AUTOSAR XML (schema 4-3-0)
package /DBCImport/CANTP
  can tp config CanTpConfig_Project: communication-cluster=Project, can-tp-ecu=ECU1
    4 x can tp channel, all with channel-mode=HALF-DUPLEX-MODE:
      CanTpChannel{0..3}: channel-id={0..3}
    tp-connections:
      addressing-format=STANDARD, can-tp-channel=CanTpChannel1, data-pdu=NPdu_GST_Msg_TP2, flow-control-pdu=NPdu_ECU1_Msg_TP2, max-block-size=0, padding-activation=true, ta-type=PHYSICAL, tp-sdu=ISignalIPdu_GST_Msg_TP2
      addressing-format=STANDARD, can-tp-channel=CanTpChannel0, data-pdu=NPdu_GST_Msg_TP1, flow-control-pdu=NPdu_ECU1_Msg_TP1, max-block-size=0, padding-activation=true, ta-type=PHYSICAL, tp-sdu=ISignalIPdu_GST_Msg_TP1
      addressing-format=STANDARD, can-tp-channel=CanTpChannel2, data-pdu=NPdu_ECU1_GST_Msg_TP, flow-control-pdu=NPdu_GST_Msg_TP_Phys, max-block-size=0, padding-activation=true, ta-type=PHYSICAL, tp-sdu=DcmIPdu_ECU1_GST_Msg_TP
      addressing-format=STANDARD, can-tp-channel=CanTpChannel2, data-pdu=NPdu_GST_Msg_TP_Phys, flow-control-pdu=NPdu_ECU1_GST_Msg_TP, max-block-size=0, padding-activation=true, ta-type=PHYSICAL, tp-sdu=DcmIPdu_GST_Msg_TP_Phys
      addressing-format=STANDARD, can-tp-channel=CanTpChannel1, data-pdu=NPdu_ECU1_Msg_TP2, flow-control-pdu=NPdu_GST_Msg_TP2, max-block-size=0, padding-activation=true, ta-type=PHYSICAL, tp-sdu=ISignalIPdu_ECU1_Msg_TP2
      addressing-format=STANDARD, can-tp-channel=CanTpChannel3, data-pdu=NPdu_GST_Msg_TP_Func, max-block-size=0, padding-activation=true, ta-type=FUNCTIONAL, tp-sdu=DcmIPdu_GST_Msg_TP_Func
      addressing-format=STANDARD, can-tp-channel=CanTpChannel0, data-pdu=NPdu_ECU1_Msg_TP1, flow-control-pdu=NPdu_GST_Msg_TP1, max-block-size=0, padding-activation=true, ta-type=PHYSICAL, tp-sdu=ISignalIPdu_ECU1_Msg_TP1
    can tp node ECU1: connector=Conn_ECU1_Project
package /DBCImport/SWCComposition
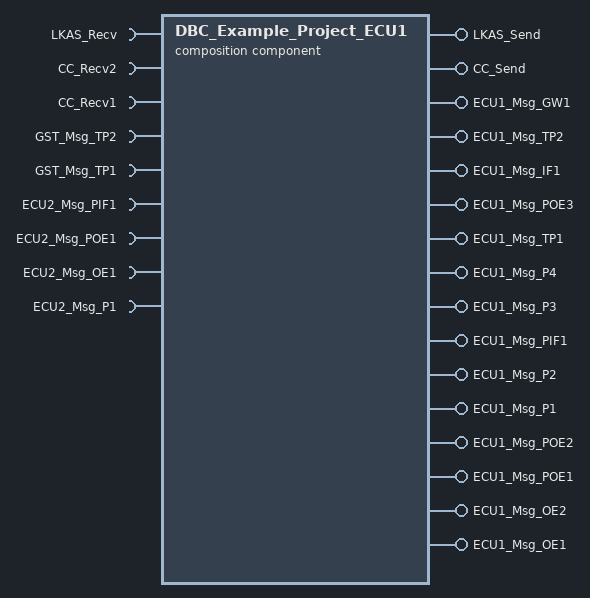
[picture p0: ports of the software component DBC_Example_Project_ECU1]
  composition sw component type DBC_Example_Project_ECU1
    16 x provide port:
      LKAS_Send: provided-interface=LKAS_Send
      CC_Send: provided-interface=CC_Send
      ECU1_Msg_GW1: provided-interface=ECU1_Msg_GW1
      ECU1_Msg_TP2: provided-interface=ECU1_Msg_TP2
      ECU1_Msg_IF1: provided-interface=ECU1_Msg_IF1
      ECU1_Msg_POE3: provided-interface=ECU1_Msg_POE3
      ECU1_Msg_TP1: provided-interface=ECU1_Msg_TP1
      ECU1_Msg_P4: provided-interface=ECU1_Msg_P4
      ECU1_Msg_P3: provided-interface=ECU1_Msg_P3
      ECU1_Msg_PIF1: provided-interface=ECU1_Msg_PIF1
      ECU1_Msg_P2: provided-interface=ECU1_Msg_P2
      ECU1_Msg_P1: provided-interface=ECU1_Msg_P1
      ECU1_Msg_POE2: provided-interface=ECU1_Msg_POE2
      ECU1_Msg_POE1: provided-interface=ECU1_Msg_POE1
      ECU1_Msg_OE2: provided-interface=ECU1_Msg_OE2
      ECU1_Msg_OE1: provided-interface=ECU1_Msg_OE1
    9 x require port:
      LKAS_Recv: required-interface=LKAS_Recv
      CC_Recv2: required-interface=CC_Recv2
      CC_Recv1: required-interface=CC_Recv1
      GST_Msg_TP2: required-interface=GST_Msg_TP2
      GST_Msg_TP1: required-interface=GST_Msg_TP1
      ECU2_Msg_PIF1: required-interface=ECU2_Msg_PIF1
      ECU2_Msg_POE1: required-interface=ECU2_Msg_POE1
      ECU2_Msg_OE1: required-interface=ECU2_Msg_OE1
      ECU2_Msg_P1: required-interface=ECU2_Msg_P1
package /DBCImport/CLUSTERS
  can cluster Project: baudrate=500000, protocol-name=CAN, speed=500
    can physical channel Project: comm-connectors=Conn_ECU1_Project
      frame CanFrame_LKAS_Send: id 0x7FE, frame-length=8, can-addressing-mode=STANDARD, can-fd-frame-support=false
        pdu ISignalIPdu_LKAS_Send: length=8, minimum-delay=0.02, transmission-mode-true-timing=event-controlled-timing={number-of-repetitions=3, repetition-period=0.04}
          signal ISignal_LKAS_Send_RIGHT_STEER: start 32, 32 bit, little-endian, init-value=0, base-type=sint32, compu {phys=raw for raw 0}, transfer-property=TRIGGERED-WITHOUT-REPETITION
          signal ISignal_LKAS_Send_LEFT_STEER: start 0, 32 bit, little-endian, init-value=0, base-type=sint32, compu {phys=raw for raw 0}, transfer-property=TRIGGERED-WITHOUT-REPETITION
      frame CanFrame_LKAS_Recv: id 0x7FC, frame-length=8, can-addressing-mode=STANDARD, can-fd-frame-support=false
        pdu ISignalIPdu_LKAS_Recv: length=8, minimum-delay=0.02, transmission-mode-true-timing=event-controlled-timing={number-of-repetitions=3, repetition-period=0.04}
          signal ISignal_LKAS_Recv_STEER_VALUE: start 32, 32 bit, little-endian, init-value=0, base-type=sint32, compu {phys=raw for raw 0}, transfer-property=TRIGGERED-ON-CHANGE-WITHOUT-REPETITION
          signal ISignal_LKAS_Recv_LKAS_TRIGGER: start 0, 32 bit, little-endian, init-value=0, base-type=sint32, compu {phys=raw for raw 0}, transfer-property=TRIGGERED-ON-CHANGE-WITHOUT-REPETITION
      frame CanFrame_CC_Send: id 0x7FF, frame-length=8, can-addressing-mode=STANDARD, can-fd-frame-support=false
        pdu ISignalIPdu_CC_Send: length=8, minimum-delay=0.02, transmission-mode-true-timing=event-controlled-timing={number-of-repetitions=3, repetition-period=0.04}
          signal ISignal_CC_Send_BRAKE: start 32, 32 bit, little-endian, init-value=0, base-type=sint32, compu {phys=raw for raw 0}, transfer-property=TRIGGERED-ON-CHANGE-WITHOUT-REPETITION
          signal ISignal_CC_Send_ACCEL: start 0, 32 bit, little-endian, init-value=0, base-type=sint32, compu {phys=raw for raw 0}, transfer-property=TRIGGERED-WITHOUT-REPETITION
      frame CanFrame_CC_Recv2: id 0x7FD, frame-length=8, can-addressing-mode=STANDARD, can-fd-frame-support=false
        pdu ISignalIPdu_CC_Recv2: length=8, minimum-delay=0.02, transmission-mode-true-timing=event-controlled-timing={number-of-repetitions=3, repetition-period=0.04}
          signal ISignal_CC_Recv2_SPEED: start 32, 32 bit, little-endian, init-value=0, base-type=sint32, compu {phys=raw for raw 0}, transfer-property=TRIGGERED-ON-CHANGE-WITHOUT-REPETITION
          signal ISignal_CC_Recv2_CC_TRIGGER: start 0, 32 bit, little-endian, init-value=0, base-type=sint32, compu {phys=raw for raw 0}, transfer-property=TRIGGERED-ON-CHANGE-WITHOUT-REPETITION
      frame CanFrame_CC_Recv1: id 0x7EF, frame-length=8, can-addressing-mode=STANDARD, can-fd-frame-support=false
        pdu ISignalIPdu_CC_Recv1: length=8, minimum-delay=0.02, transmission-mode-true-timing=event-controlled-timing={number-of-repetitions=3, repetition-period=0.04}
          signal ISignal_CC_Recv1_ACCEL_VALUE: start 32, 32 bit, little-endian, init-value=0, base-type=uint32, compu {phys=raw for raw 0}, transfer-property=TRIGGERED-ON-CHANGE-WITHOUT-REPETITION
          signal ISignal_CC_Recv1_TARGET_SPEED: start 0, 32 bit, little-endian, init-value=0, base-type=sint32, compu {phys=raw for raw 0}, transfer-property=TRIGGERED-ON-CHANGE-WITHOUT-REPETITION
      frame CanFrame_GST_Msg_TP2: id 0x707, frame-length=8, can-addressing-mode=STANDARD, can-fd-frame-support=false
        pdu ISignalIPdu_GST_Msg_TP2: length=8, minimum-delay=0.0, transmission-mode-true-timing=event-controlled-timing={number-of-repetitions=0, repetition-period=0.0}
          signal ISignal_GST_Msg_TP2_GST_Msg_TP2_signal: start 0, 64 bit, opaque, init-value=8 x 0, compu {phys=raw for raw 0}, implementation-data-type=array8uint8, transfer-property=TRIGGERED-WITHOUT-REPETITION
        n pdu NPdu_GST_Msg_TP2: length=8, meta-data-length=0
      frame CanFrame_GST_Msg_TP1: id 0x706, frame-length=8, can-addressing-mode=STANDARD, can-fd-frame-support=false
        pdu ISignalIPdu_GST_Msg_TP1: length=8, minimum-delay=0.0, transmission-mode-true-timing=event-controlled-timing={number-of-repetitions=0, repetition-period=0.0}
          signal ISignal_GST_Msg_TP1_GST_Msg_TP1_signal: start 0, 64 bit, opaque, init-value=8 x 0, compu {phys=raw for raw 0}, implementation-data-type=array8uint8, transfer-property=TRIGGERED-WITHOUT-REPETITION
        n pdu NPdu_GST_Msg_TP1: length=8, meta-data-length=0
      frame CanFrame_ECU1_GST_Msg_TP: id 0x705, frame-length=8, can-addressing-mode=STANDARD, can-fd-frame-support=false
        dcm i pdu DcmIPdu_ECU1_GST_Msg_TP: length=8
        n pdu NPdu_ECU1_GST_Msg_TP: length=8, meta-data-length=0
      frame CanFrame_ECU1_Msg_GW1: id 0x55, frame-length=8, can-addressing-mode=STANDARD, can-fd-frame-support=false
        pdu ISignalIPdu_ECU1_Msg_GW1: length=8, minimum-delay=0.02, transmission-mode-true-timing=event-controlled-timing={number-of-repetitions=3, repetition-period=0.04}
          signal ISignal_ECU1_Msg_GW1_ECU1_Msg_GW1_Sig2: start 15, 8 bit, big-endian, init-value=0, base-type=uint8, compu {phys=raw for raw 0}, transfer-property=TRIGGERED
          signal ISignal_ECU1_Msg_GW1_ECU1_Msg_GW1_Sig1: start 7, 8 bit, big-endian, init-value=0, base-type=uint8, compu {phys=raw for raw 0}, transfer-property=TRIGGERED
      frame CanFrame_GST_Msg_TP_Phys: id 0x703, frame-length=8, can-addressing-mode=STANDARD, can-fd-frame-support=false
        dcm i pdu DcmIPdu_GST_Msg_TP_Phys: length=8
        n pdu NPdu_GST_Msg_TP_Phys: length=8, meta-data-length=0
      frame CanFrame_ECU1_Msg_TP2: id 0x704, frame-length=8, can-addressing-mode=STANDARD, can-fd-frame-support=false
        pdu ISignalIPdu_ECU1_Msg_TP2: length=8, minimum-delay=0.0, transmission-mode-true-timing=event-controlled-timing={number-of-repetitions=0, repetition-period=0.0}
          signal ISignal_ECU1_Msg_TP2_ECU1_Msg_TP2_signal: start 0, 64 bit, opaque, init-value=8 x 0, compu {phys=raw for raw 0}, implementation-data-type=array8uint8, transfer-property=TRIGGERED-WITHOUT-REPETITION
        n pdu NPdu_ECU1_Msg_TP2: length=8, meta-data-length=0
      frame CanFrame_ECU2_Msg_PIF1: id 0x301, frame-length=8, can-addressing-mode=STANDARD, can-fd-frame-support=false
        pdu ISignalIPdu_ECU2_Msg_PIF1: length=8, minimum-delay=0.02, transmission-mode-true-timing={cyclic-timing={time-offset=0.0, time-period=0.5}, event-controlled-timing={number-of-repetitions=3, repetition-period=0.2}}
          signal ISignal_ECU2_Msg_PIF1_ECU2_Msg_PIF1_Sig2: start 31, 8 bit, big-endian, init-value=0, base-type=uint8, compu {phys=raw for raw 0}, transfer-property=TRIGGERED
          signal ISignal_ECU2_Msg_PIF1_ECU2_Msg_PIF1_Sig1: start 23, 8 bit, big-endian, init-value=0, base-type=uint8, compu {phys=raw for raw 0}, transfer-property=TRIGGERED
      frame CanFrame_ECU2_Msg_POE1: id 0x103, frame-length=8, can-addressing-mode=STANDARD, can-fd-frame-support=false
        pdu ISignalIPdu_ECU2_Msg_POE1: length=8, minimum-delay=0.02, transmission-mode-true-timing={cyclic-timing={time-offset=0.0, time-period=0.5}, event-controlled-timing={number-of-repetitions=3, repetition-period=0.04}}
          signal ISignal_ECU2_Msg_POE1_ECU2_Msg_POE1_Sig1: start 31, 8 bit, big-endian, init-value=0, base-type=uint8, compu {phys=raw for raw 0}, transfer-property=TRIGGERED
          signal ISignal_ECU2_Msg_POE1_ECU2_Msg_POE1_Sig2: start 23, 8 bit, big-endian, init-value=0, base-type=uint8, compu {phys=raw for raw 0}, transfer-property=TRIGGERED-ON-CHANGE
      frame CanFrame_ECU1_Msg_IF1: id 0x200, frame-length=8, can-addressing-mode=STANDARD, can-fd-frame-support=false
        pdu ISignalIPdu_ECU1_Msg_IF1: length=8, minimum-delay=0.02, transmission-mode-true-timing=event-controlled-timing={number-of-repetitions=3, repetition-period=0.2}
          signal ISignal_ECU1_Msg_IF1_ECU1_Msg_IF1_Sig2: start 15, 8 bit, big-endian, init-value=0, base-type=uint8, compu {phys=raw for raw 0}, transfer-property=TRIGGERED
          signal ISignal_ECU1_Msg_IF1_ECU1_Msg_IF1_Sig1: start 7, 8 bit, big-endian, init-value=0, base-type=uint8, compu {phys=raw for raw 0}, transfer-property=TRIGGERED
      frame CanFrame_ECU2_Msg_OE1: id 0x3, frame-length=8, can-addressing-mode=STANDARD, can-fd-frame-support=false
        pdu ISignalIPdu_ECU2_Msg_OE1: length=8, minimum-delay=0.02, transmission-mode-true-timing=event-controlled-timing={number-of-repetitions=3, repetition-period=0.04}
          signal ISignal_ECU2_Msg_OE1_ECU2_Msg_OE1_Sig2: start 15, 8 bit, big-endian, init-value=0, base-type=uint8, compu {phys=raw for raw 0}, transfer-property=TRIGGERED-WITHOUT-REPETITION
          signal ISignal_ECU2_Msg_OE1_ECU2_Msg_OE1_Sig1: start 7, 8 bit, big-endian, init-value=0, base-type=uint8, compu {phys=raw for raw 0}, transfer-property=TRIGGERED-WITHOUT-REPETITION
      frame CanFrame_ECU2_Msg_P1: id 0x503, frame-length=2, can-addressing-mode=STANDARD, can-fd-frame-support=false
        pdu ISignalIPdu_ECU2_Msg_P1: length=2, minimum-delay=0.02, transmission-mode-true-timing=cyclic-timing={time-offset=0.0, time-period=0.5}
          signal ISignal_ECU2_Msg_P1_ECU2_Msg_P1_Sig2: start 15, 8 bit, big-endian, init-value=0, base-type=uint8, compu {phys=raw for raw 0}, transfer-property=PENDING
          signal ISignal_ECU2_Msg_P1_ECU2_Msg_P1_Sig1: start 7, 8 bit, big-endian, init-value=0, base-type=uint8, compu {phys=raw for raw 0}, transfer-property=PENDING
      frame CanFrame_ECU1_Msg_POE3: id 0x100, frame-length=8, can-addressing-mode=STANDARD, can-fd-frame-support=false
        pdu ISignalIPdu_ECU1_Msg_POE3: length=8, minimum-delay=0.02, transmission-mode-true-timing={cyclic-timing={time-offset=0.0, time-period=0.2}, event-controlled-timing={number-of-repetitions=3, repetition-period=0.04}}
          signal ISignal_ECU1_Msg_POE3_ECU1_Msg_POE3_Sig2: start 15, 8 bit, big-endian, init-value=0, base-type=uint8, compu {phys=raw for raw 0}, transfer-property=TRIGGERED-ON-CHANGE-WITHOUT-REPETITION
          signal ISignal_ECU1_Msg_POE3_ECU1_Msg_POE3_Sig1: start 7, 8 bit, big-endian, init-value=0, base-type=uint8, compu {phys=raw for raw 0..255}, transfer-property=TRIGGERED-WITHOUT-REPETITION
      frame CanFrame_GST_Msg_TP_Func: id 0x7DF, frame-length=8, can-addressing-mode=STANDARD, can-fd-frame-support=false
        dcm i pdu DcmIPdu_GST_Msg_TP_Func: length=8
        n pdu NPdu_GST_Msg_TP_Func: length=8, meta-data-length=0
      frame CanFrame_ECU1_Msg_TP1: id 0x701, frame-length=8, can-addressing-mode=STANDARD, can-fd-frame-support=false
        pdu ISignalIPdu_ECU1_Msg_TP1: length=8, minimum-delay=0.0, transmission-mode-true-timing=event-controlled-timing={number-of-repetitions=0, repetition-period=0.0}
          signal ISignal_ECU1_Msg_TP1_ECU1_Msg_TP1_signal: start 0, 64 bit, opaque, init-value=8 x 0, compu {phys=raw for raw 0}, implementation-data-type=array8uint8, transfer-property=TRIGGERED-WITHOUT-REPETITION
        n pdu NPdu_ECU1_Msg_TP1: length=8, meta-data-length=0
      frame CanFrame_ECU1_Msg_P4: id 0x602, frame-length=8, can-addressing-mode=STANDARD, can-fd-frame-support=false
        pdu ISignalIPdu_ECU1_Msg_P4: length=8, minimum-delay=0.02, transmission-mode-true-timing=cyclic-timing={time-offset=0.0, time-period=0.2}
          signal ISignal_ECU1_Msg_P4_ECU1_Msg_P4_Sig2: start 15, 8 bit, big-endian, init-value=0, base-type=uint8, compu {phys=raw for raw 0}, transfer-property=PENDING
          signal ISignal_ECU1_Msg_P4_ECU1_Msg_P4_Sig1: start 7, 8 bit, big-endian, init-value=0, base-type=uint8, compu {phys=raw for raw 0}, transfer-property=PENDING
      frame CanFrame_ECU1_Msg_P3: id 0x601, frame-length=8, can-addressing-mode=STANDARD, can-fd-frame-support=false
        pdu ISignalIPdu_ECU1_Msg_P3: length=8, minimum-delay=0.02, transmission-mode-true-timing=cyclic-timing={time-offset=0.0, time-period=0.2}
          signal ISignal_ECU1_Msg_P3_ECU1_Msg_P3_Sig2: start 15, 8 bit, big-endian, init-value=0, base-type=uint8, compu {phys=raw for raw 0}, transfer-property=PENDING
          signal ISignal_ECU1_Msg_P3_ECU1_Msg_P3_Sig1: start 7, 8 bit, big-endian, init-value=0, base-type=uint8, compu {phys=raw for raw 0}, transfer-property=PENDING
      frame CanFrame_ECU1_Msg_PIF1: id 0x300, frame-length=8, can-addressing-mode=STANDARD, can-fd-frame-support=false
        pdu ISignalIPdu_ECU1_Msg_PIF1: length=8, minimum-delay=0.02, transmission-mode-true-timing={cyclic-timing={time-offset=0.0, time-period=0.5}, event-controlled-timing={number-of-repetitions=3, repetition-period=0.2}}
          signal ISignal_ECU1_Msg_PIF1_ECU1_Msg_PIF1_Sig2: start 15, 8 bit, big-endian, init-value=0, base-type=uint8, compu {phys=raw for raw 0}, transfer-property=TRIGGERED
          signal ISignal_ECU1_Msg_PIF1_ECU1_Msg_PIF1_Sig1: start 7, 8 bit, big-endian, init-value=0, base-type=uint8, compu {phys=raw for raw 0}, transfer-property=TRIGGERED
      frame CanFrame_ECU1_Msg_P2: id 0x502, frame-length=8, can-addressing-mode=STANDARD, can-fd-frame-support=false
        pdu ISignalIPdu_ECU1_Msg_P2: length=8, minimum-delay=0.02, transmission-mode-true-timing=cyclic-timing={time-offset=0.0, time-period=0.2}
          signal ISignal_ECU1_Msg_P2_ECU1_Msg_P2_Sig2: start 15, 8 bit, big-endian, init-value=0, base-type=uint8, compu {phys=raw for raw 0}, transfer-property=PENDING
          signal ISignal_ECU1_Msg_P2_ECU1_Msg_P2_Sig1: start 7, 8 bit, big-endian, init-value=0, base-type=uint8, compu {phys=raw for raw 0}, transfer-property=PENDING
      frame CanFrame_ECU1_Msg_P1: id 0x501, frame-length=8, can-addressing-mode=STANDARD, can-fd-frame-support=false
        pdu ISignalIPdu_ECU1_Msg_P1: length=8, minimum-delay=0.02, transmission-mode-true-timing=cyclic-timing={time-offset=0.0, time-period=0.5}
          signal ISignal_ECU1_Msg_P1_ECU1_Msg_P1_Sig2: start 15, 8 bit, big-endian, init-value=0, base-type=uint8, compu {phys=raw for raw 0}, transfer-property=PENDING
          signal ISignal_ECU1_Msg_P1_ECU1_Msg_P1_Sig1: start 7, 8 bit, big-endian, init-value=0, base-type=uint8, compu {phys=raw for raw 0}, transfer-property=PENDING
      frame CanFrame_ECU1_Msg_POE2: id 0x102, frame-length=8, can-addressing-mode=STANDARD, can-fd-frame-support=false
        pdu ISignalIPdu_ECU1_Msg_POE2: length=8, minimum-delay=0.02, transmission-mode-true-timing={cyclic-timing={time-offset=0.0, time-period=0.2}, event-controlled-timing={number-of-repetitions=3, repetition-period=0.04}}
          signal ISignal_ECU1_Msg_POE2_ECU1_Msg_POE2_Sig2: start 15, 8 bit, big-endian, init-value=0, base-type=uint8, compu {phys=raw for raw 0}, transfer-property=TRIGGERED-ON-CHANGE
          signal ISignal_ECU1_Msg_POE2_ECU1_Msg_POE2_Sig1: start 7, 8 bit, big-endian, init-value=0, base-type=uint8, compu {phys=raw for raw 0}, transfer-property=TRIGGERED
      frame CanFrame_ECU1_Msg_POE1: id 0x101, frame-length=8, can-addressing-mode=STANDARD, can-fd-frame-support=false
        pdu ISignalIPdu_ECU1_Msg_POE1: length=8, minimum-delay=0.02, transmission-mode-true-timing={cyclic-timing={time-offset=0.0, time-period=0.2}, event-controlled-timing={number-of-repetitions=3, repetition-period=0.04}}
          signal ISignal_ECU1_Msg_POE1_ECU1_Msg_POE1_Sig2: start 15, 8 bit, big-endian, init-value=0, base-type=uint8, compu {phys=raw for raw 0}, transfer-property=TRIGGERED-ON-CHANGE-WITHOUT-REPETITION
          signal ISignal_ECU1_Msg_POE1_ECU1_Msg_POE1_Sig1: start 7, 8 bit, big-endian, init-value=0, base-type=uint8, compu {phys=raw for raw 0}, transfer-property=TRIGGERED-WITHOUT-REPETITION
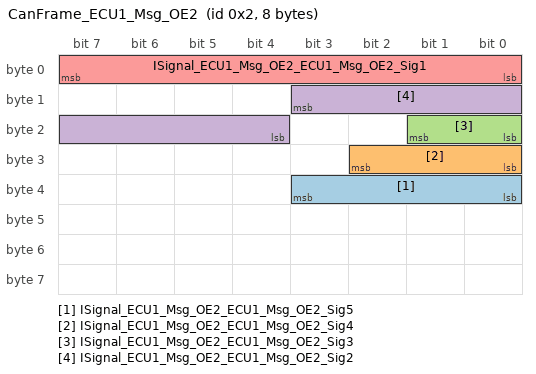
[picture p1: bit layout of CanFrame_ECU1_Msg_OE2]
      frame CanFrame_ECU1_Msg_OE2: id 0x2, frame-length=8, can-addressing-mode=STANDARD, can-fd-frame-support=false
        pdu ISignalIPdu_ECU1_Msg_OE2: length=8, minimum-delay=0.02, transmission-mode-true-timing=event-controlled-timing={number-of-repetitions=3, repetition-period=0.04}
          signal ISignal_ECU1_Msg_OE2_ECU1_Msg_OE2_Sig5: start 35, 4 bit, big-endian, init-value=0, base-type=uint8, compu {phys=raw for raw 0..15}, transfer-property=TRIGGERED-ON-CHANGE
          signal ISignal_ECU1_Msg_OE2_ECU1_Msg_OE2_Sig4: start 26, 3 bit, big-endian, init-value=0, base-type=uint8, compu {phys=raw for raw 0..7}, transfer-property=TRIGGERED-ON-CHANGE
          signal ISignal_ECU1_Msg_OE2_ECU1_Msg_OE2_Sig3: start 17, 2 bit, big-endian, init-value=0, base-type=uint8, compu {phys=raw for raw 0..3}, transfer-property=TRIGGERED-ON-CHANGE
          signal ISignal_ECU1_Msg_OE2_ECU1_Msg_OE2_Sig2: start 11, 8 bit, big-endian, init-value=0, base-type=uint8, compu {phys=raw for raw 0}, transfer-property=TRIGGERED-ON-CHANGE
          signal ISignal_ECU1_Msg_OE2_ECU1_Msg_OE2_Sig1: start 7, 8 bit, big-endian, init-value=0, base-type=uint8, compu {phys=raw for raw 0}, transfer-property=TRIGGERED
      frame CanFrame_ECU1_Msg_OE1: id 0x1, frame-length=8, can-addressing-mode=STANDARD, can-fd-frame-support=false
        pdu ISignalIPdu_ECU1_Msg_OE1: length=8, minimum-delay=0.02, transmission-mode-true-timing=event-controlled-timing={number-of-repetitions=3, repetition-period=0.04}
          signal ISignal_ECU1_Msg_OE1_ECU1_Msg_OE1_Sig2: start 12, 8 bit, little-endian, init-value=0, base-type=uint8, compu {phys=raw for raw 0}, transfer-property=TRIGGERED-ON-CHANGE-WITHOUT-REPETITION
          signal ISignal_ECU1_Msg_OE1_ECU1_Msg_OE1_Sig1: start 7, 8 bit, big-endian, init-value=0, base-type=uint8, compu {phys=raw for raw 0}, transfer-property=TRIGGERED-WITHOUT-REPETITION
package /DBCImport/IPDUGROUPS
  i signal i pdu group ISignalIPduGroupRx_ECU1_Project: communication-direction=IN, communication-mode=rx
    i-signal-i-pdus:
      ISignalIPdu_LKAS_Recv
      ISignalIPdu_CC_Recv2
      ISignalIPdu_CC_Recv1
      ISignalIPdu_GST_Msg_TP2
      ISignalIPdu_GST_Msg_TP1
      ISignalIPdu_ECU2_Msg_PIF1
      ISignalIPdu_ECU2_Msg_POE1
      ISignalIPdu_ECU2_Msg_OE1
      ISignalIPdu_ECU2_Msg_P1
  i signal i pdu group ISignalIPduGroupTx_ECU1_Project: communication-direction=OUT, communication-mode=tx
    i-signal-i-pdus:
      ISignalIPdu_LKAS_Send
      ISignalIPdu_CC_Send
      ISignalIPdu_ECU1_Msg_GW1
      ISignalIPdu_ECU1_Msg_TP2
      ISignalIPdu_ECU1_Msg_IF1
      ISignalIPdu_ECU1_Msg_POE3
      ISignalIPdu_ECU1_Msg_TP1
      ISignalIPdu_ECU1_Msg_P4
      ISignalIPdu_ECU1_Msg_P3
      ISignalIPdu_ECU1_Msg_PIF1
      ISignalIPdu_ECU1_Msg_P2
      ISignalIPdu_ECU1_Msg_P1
      ISignalIPdu_ECU1_Msg_POE2
      ISignalIPdu_ECU1_Msg_POE1
      ISignalIPdu_ECU1_Msg_OE2
      ISignalIPdu_ECU1_Msg_OE1
package /DBCImport/INTERFACES
  25 x sender receiver interface:
    CC_Recv1
      data ACCEL_VALUE: base-type=uint32, compu {phys=raw for raw 0}, type=uint32, init-value=0
      data TARGET_SPEED: base-type=sint32, compu {phys=raw for raw 0}, type=sint32, init-value=0
    CC_Recv2
      data SPEED: base-type=sint32, compu {phys=raw for raw 0}, type=sint32, init-value=0
      data CC_TRIGGER: base-type=sint32, compu {phys=raw for raw 0}, type=sint32, init-value=0
    CC_Send
      data BRAKE: base-type=sint32, compu {phys=raw for raw 0}, type=sint32, init-value=0
      data ACCEL: base-type=sint32, compu {phys=raw for raw 0}, type=sint32, init-value=0
    ECU1_Msg_GW1
      data ECU1_Msg_GW1_Sig2: base-type=uint8, compu {phys=raw for raw 0}, type=uint8, init-value=0
      data ECU1_Msg_GW1_Sig1: base-type=uint8, compu {phys=raw for raw 0}, type=uint8, init-value=0
    ECU1_Msg_IF1
      data ECU1_Msg_IF1_Sig2: base-type=uint8, compu {phys=raw for raw 0}, type=uint8, init-value=0
      data ECU1_Msg_IF1_Sig1: base-type=uint8, compu {phys=raw for raw 0}, type=uint8, init-value=0
    ECU1_Msg_OE1
      data ECU1_Msg_OE1_Sig2: base-type=uint8, compu {phys=raw for raw 0}, type=uint8, init-value=0
      data ECU1_Msg_OE1_Sig1: base-type=uint8, compu {phys=raw for raw 0}, type=uint8, init-value=0
    ECU1_Msg_OE2
      5 x data, all with base-type=uint8, type=uint8, init-value=0:
        ECU1_Msg_OE2_Sig5: compu {phys=raw for raw 0..15}
        ECU1_Msg_OE2_Sig4: compu {phys=raw for raw 0..7}
        ECU1_Msg_OE2_Sig3: compu {phys=raw for raw 0..3}
        ECU1_Msg_OE2_Sig2: compu {phys=raw for raw 0}
        ECU1_Msg_OE2_Sig1: compu {phys=raw for raw 0}
    ECU1_Msg_P1
      data ECU1_Msg_P1_Sig2: base-type=uint8, compu {phys=raw for raw 0}, type=uint8, init-value=0
      data ECU1_Msg_P1_Sig1: base-type=uint8, compu {phys=raw for raw 0}, type=uint8, init-value=0
    ECU1_Msg_P2
      data ECU1_Msg_P2_Sig2: base-type=uint8, compu {phys=raw for raw 0}, type=uint8, init-value=0
      data ECU1_Msg_P2_Sig1: base-type=uint8, compu {phys=raw for raw 0}, type=uint8, init-value=0
    ECU1_Msg_P3
      data ECU1_Msg_P3_Sig2: base-type=uint8, compu {phys=raw for raw 0}, type=uint8, init-value=0
      data ECU1_Msg_P3_Sig1: base-type=uint8, compu {phys=raw for raw 0}, type=uint8, init-value=0
    ECU1_Msg_P4
      data ECU1_Msg_P4_Sig2: base-type=uint8, compu {phys=raw for raw 0}, type=uint8, init-value=0
      data ECU1_Msg_P4_Sig1: base-type=uint8, compu {phys=raw for raw 0}, type=uint8, init-value=0
    ECU1_Msg_PIF1
      data ECU1_Msg_PIF1_Sig2: base-type=uint8, compu {phys=raw for raw 0}, type=uint8, init-value=0
      data ECU1_Msg_PIF1_Sig1: base-type=uint8, compu {phys=raw for raw 0}, type=uint8, init-value=0
    ECU1_Msg_POE1
      data ECU1_Msg_POE1_Sig2: base-type=uint8, compu {phys=raw for raw 0}, type=uint8, init-value=0
      data ECU1_Msg_POE1_Sig1: base-type=uint8, compu {phys=raw for raw 0}, type=uint8, init-value=0
    ECU1_Msg_POE2
      data ECU1_Msg_POE2_Sig2: base-type=uint8, compu {phys=raw for raw 0}, type=uint8, init-value=0
      data ECU1_Msg_POE2_Sig1: base-type=uint8, compu {phys=raw for raw 0}, type=uint8, init-value=0
    ECU1_Msg_POE3
      data ECU1_Msg_POE3_Sig2: base-type=uint8, compu {phys=raw for raw 0}, type=uint8, init-value=0
      data ECU1_Msg_POE3_Sig1: base-type=uint8, compu {phys=raw for raw 0..255}, type=uint8, init-value=0
    ECU1_Msg_TP1
      data ECU1_Msg_TP1_signal: compu {phys=raw for raw 0}, sw-impl-policy=QUEUED, type=array8uint8
    ECU1_Msg_TP2
      data ECU1_Msg_TP2_signal: compu {phys=raw for raw 0}, sw-impl-policy=QUEUED, type=array8uint8
    ECU2_Msg_OE1
      data ECU2_Msg_OE1_Sig2: base-type=uint8, compu {phys=raw for raw 0}, type=uint8, init-value=0
      data ECU2_Msg_OE1_Sig1: base-type=uint8, compu {phys=raw for raw 0}, type=uint8, init-value=0
    ECU2_Msg_P1
      data ECU2_Msg_P1_Sig2: base-type=uint8, compu {phys=raw for raw 0}, type=uint8, init-value=0
      data ECU2_Msg_P1_Sig1: base-type=uint8, compu {phys=raw for raw 0}, type=uint8, init-value=0
    ECU2_Msg_PIF1
      data ECU2_Msg_PIF1_Sig2: base-type=uint8, compu {phys=raw for raw 0}, type=uint8, init-value=0
      data ECU2_Msg_PIF1_Sig1: base-type=uint8, compu {phys=raw for raw 0}, type=uint8, init-value=0
    ECU2_Msg_POE1
      data ECU2_Msg_POE1_Sig1: base-type=uint8, compu {phys=raw for raw 0}, type=uint8, init-value=0
      data ECU2_Msg_POE1_Sig2: base-type=uint8, compu {phys=raw for raw 0}, type=uint8, init-value=0
    GST_Msg_TP1
      data GST_Msg_TP1_signal: compu {phys=raw for raw 0}, sw-impl-policy=QUEUED, type=array8uint8
    GST_Msg_TP2
      data GST_Msg_TP2_signal: compu {phys=raw for raw 0}, sw-impl-policy=QUEUED, type=array8uint8
    LKAS_Recv
      data STEER_VALUE: base-type=sint32, compu {phys=raw for raw 0}, type=sint32, init-value=0
      data LKAS_TRIGGER: base-type=sint32, compu {phys=raw for raw 0}, type=sint32, init-value=0
    LKAS_Send
      data RIGHT_STEER: base-type=sint32, compu {phys=raw for raw 0}, type=sint32, init-value=0
      data LEFT_STEER: base-type=sint32, compu {phys=raw for raw 0}, type=sint32, init-value=0
package /DBCImport/ImplementationDataTypes_Project
  impl type array8uint8: category=ARRAY
    element uint8: array-size=8, array-size-semantics=FIXED-SIZE, implementation-data-type=uint8
